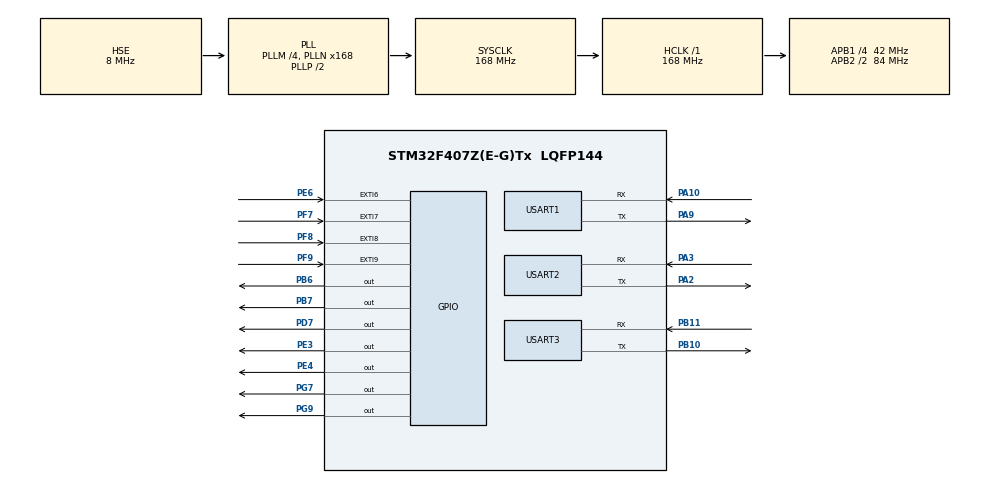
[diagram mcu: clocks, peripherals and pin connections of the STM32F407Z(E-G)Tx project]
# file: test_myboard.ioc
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Mcu.Family=STM32F4
Mcu.Name=STM32F407Z(E-G)Tx
Mcu.Package=LQFP144
NVIC.EXTI9_5_IRQn=true\:0\:0\:false\:false\:true\:true\:true
NVIC.FLASH_IRQn=true\:0\:0\:false\:false\:true\:true\:true
NVIC.FPU_IRQn=true\:0\:0\:false\:false\:true\:true\:false
NVIC.PVD_IRQn=true\:0\:0\:false\:false\:true\:true\:true
NVIC.PriorityGroup=NVIC_PRIORITYGROUP_2
NVIC.RCC_IRQn=true\:0\:0\:false\:false\:true\:true\:false
NVIC.TIM1_UP_TIM10_IRQn=true\:0\:0\:false\:false\:true\:false\:true
NVIC.TimeBase=TIM1_UP_TIM10_IRQn
NVIC.TimeBaseIP=TIM1
NVIC.USART1_IRQn=true\:0\:0\:false\:false\:true\:true\:true
NVIC.USART2_IRQn=true\:0\:0\:false\:false\:true\:true\:true
NVIC.USART3_IRQn=true\:0\:0\:false\:false\:true\:true\:true
PA10.Mode=Asynchronous
PA10.Signal=USART1_RX
PA2.Mode=Asynchronous
PA2.Signal=USART2_TX
PA3.Mode=Asynchronous
PA3.Signal=USART2_RX
PA9.Mode=Asynchronous
PA9.Signal=USART1_TX
PB10.Mode=Asynchronous
PB10.Signal=USART3_TX
PB11.Mode=Asynchronous
PB11.Signal=USART3_RX
PB6.Signal=GPIO_Output
PB7.Signal=GPIO_Output
PC14-OSC32_IN.Mode=LSE-External-Oscillator
PC14-OSC32_IN.Signal=RCC_OSC32_IN
PC15-OSC32_OUT.Mode=LSE-External-Oscillator
PC15-OSC32_OUT.Signal=RCC_OSC32_OUT
PD7.PinState=GPIO_PIN_RESET
PD7.Signal=GPIO_Output
PE3.PinState=GPIO_PIN_SET
PE3.Signal=GPIO_Output
PE4.PinState=GPIO_PIN_SET
PE4.Signal=GPIO_Output
PE6.GPIO_ModeDefaultEXTI=GPIO_MODE_IT_FALLING
PE6.Signal=GPXTI6
PF7.GPIO_ModeDefaultEXTI=GPIO_MODE_IT_FALLING
PF7.Signal=GPXTI7
PF8.GPIO_ModeDefaultEXTI=GPIO_MODE_IT_FALLING
PF8.Signal=GPXTI8
PF9.GPIO_ModeDefaultEXTI=GPIO_MODE_IT_FALLING
PF9.Signal=GPXTI9
PG7.Signal=GPIO_Output
PG9.PinState=GPIO_PIN_SET
PG9.Signal=GPIO_Output
PH0-OSC_IN.Mode=HSE-External-Oscillator
PH0-OSC_IN.Signal=RCC_OSC_IN
PH1-OSC_OUT.Mode=HSE-External-Oscillator
PH1-OSC_OUT.Signal=RCC_OSC_OUT
ProjectManager.HeapSize=0x200
ProjectManager.StackSize=0x400
ProjectManager.TargetToolchain=MDK-ARM V5.27
RCC.48MHZClocksFreq_Value=84000000
RCC.AHBFreq_Value=168000000
RCC.APB1CLKDivider=RCC_HCLK_DIV4
RCC.APB1Freq_Value=42000000
RCC.APB1TimFreq_Value=84000000
RCC.APB2CLKDivider=RCC_HCLK_DIV2
RCC.APB2Freq_Value=84000000
RCC.APB2TimFreq_Value=168000000
RCC.CortexFreq_Value=168000000
RCC.HCLKFreq_Value=168000000
RCC.HSE_VALUE=8000000
RCC.HSI_VALUE=16000000
RCC.PLLM=4
RCC.PLLN=168
RCC.PLLSourceVirtual=RCC_PLLSOURCE_HSE
RCC.SYSCLKFreq_VALUE=168000000
RCC.SYSCLKSource=RCC_SYSCLKSOURCE_PLLCLK
RCC.VCOOutputFreq_Value=336000000
USART1.VirtualMode=VM_ASYNC
USART2.VirtualMode=VM_ASYNC
USART3.VirtualMode=VM_ASYNC
VP_SYS_VS_tim1.Mode=TIM1
board=custom

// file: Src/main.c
/* USER CODE BEGIN Header */
/**
  ******************************************************************************
  * @file           : main.c
  * @brief          : Main program body
  ******************************************************************************
  * @attention
  *
  * <h2><center>&copy; Copyright (c) 2020 STMicroelectronics.
  * All rights reserved.</center></h2>
  *
  * This software component is licensed by ST under BSD 3-Clause license,
  * the "License"; You may not use this file except in compliance with the
  * License. You may obtain a copy of the License at:
  *                        opensource.org/licenses/BSD-3-Clause
  *
  ******************************************************************************
  */
/* USER CODE END Header */

#include "main.h"

/* USER CODE BEGIN Includes */
#include <stdio.h>
/* USER CODE END Includes */

UART_HandleTypeDef huart1;
UART_HandleTypeDef huart2;
UART_HandleTypeDef huart3;

void SystemClock_Config(void);
static void MX_GPIO_Init(void);
static void MX_USART1_UART_Init(void);
static void MX_USART2_UART_Init(void);
static void MX_USART3_UART_Init(void);
/* USER CODE BEGIN PFP */
int fputc(int ch,FILE *f)
{
  HAL_UART_Transmit(&huart1,(uint8_t *)&ch,1,0xFFFF);
	return ch;
}
/* USER CODE END PFP */

int main(void)
{
  /* USER CODE BEGIN 1 */
 int i = 0;
  /* USER CODE END 1 */

  /* MCU Configuration--------------------------------------------------------*/

  /* Reset of all peripherals, Initializes the Flash interface and the Systick. */
  HAL_Init();

  /* Configure the system clock */
  SystemClock_Config();

  /* Initialize all configured peripherals */
  MX_GPIO_Init();
  MX_USART1_UART_Init();
  MX_USART2_UART_Init();
  MX_USART3_UART_Init();

  /* Infinite loop */
  /* USER CODE BEGIN WHILE */
  while (1)
  {
		printf("test myboard %d\r\n",i++);

		HAL_Delay(1000);
    /* USER CODE END WHILE */

  }
}

void SystemClock_Config(void)
{
  RCC_OscInitTypeDef RCC_OscInitStruct = {0};
  RCC_ClkInitTypeDef RCC_ClkInitStruct = {0};

  /** Configure the main internal regulator output voltage
  */
  __HAL_RCC_PWR_CLK_ENABLE();
  __HAL_PWR_VOLTAGESCALING_CONFIG(PWR_REGULATOR_VOLTAGE_SCALE1);
  /** Initializes the CPU, AHB and APB busses clocks
  */
  RCC_OscInitStruct.OscillatorType = RCC_OSCILLATORTYPE_HSE;
  RCC_OscInitStruct.HSEState = RCC_HSE_ON;
  RCC_OscInitStruct.PLL.PLLState = RCC_PLL_ON;
  RCC_OscInitStruct.PLL.PLLSource = RCC_PLLSOURCE_HSE;
  RCC_OscInitStruct.PLL.PLLM = 4;
  RCC_OscInitStruct.PLL.PLLN = 168;
  RCC_OscInitStruct.PLL.PLLP = RCC_PLLP_DIV2;
  RCC_OscInitStruct.PLL.PLLQ = 4;
  if (HAL_RCC_OscConfig(&RCC_OscInitStruct) != HAL_OK)
  {
    Error_Handler();
  }
  /** Initializes the CPU, AHB and APB busses clocks
  */
  RCC_ClkInitStruct.ClockType = RCC_CLOCKTYPE_HCLK|RCC_CLOCKTYPE_SYSCLK
                              |RCC_CLOCKTYPE_PCLK1|RCC_CLOCKTYPE_PCLK2;
  RCC_ClkInitStruct.SYSCLKSource = RCC_SYSCLKSOURCE_PLLCLK;
  RCC_ClkInitStruct.AHBCLKDivider = RCC_SYSCLK_DIV1;
  RCC_ClkInitStruct.APB1CLKDivider = RCC_HCLK_DIV4;
  RCC_ClkInitStruct.APB2CLKDivider = RCC_HCLK_DIV2;

  if (HAL_RCC_ClockConfig(&RCC_ClkInitStruct, FLASH_LATENCY_5) != HAL_OK)
  {
    Error_Handler();
  }
}

static void MX_USART1_UART_Init(void)
{

  huart1.Instance = USART1;
  huart1.Init.BaudRate = 115200;
  huart1.Init.WordLength = UART_WORDLENGTH_8B;
  huart1.Init.StopBits = UART_STOPBITS_1;
  huart1.Init.Parity = UART_PARITY_NONE;
  huart1.Init.Mode = UART_MODE_TX_RX;
  huart1.Init.HwFlowCtl = UART_HWCONTROL_NONE;
  huart1.Init.OverSampling = UART_OVERSAMPLING_16;
  if (HAL_UART_Init(&huart1) != HAL_OK)
  {
    Error_Handler();
  }

}

static void MX_USART2_UART_Init(void)
{

  huart2.Instance = USART2;
  huart2.Init.BaudRate = 115200;
  huart2.Init.WordLength = UART_WORDLENGTH_8B;
  huart2.Init.StopBits = UART_STOPBITS_1;
  huart2.Init.Parity = UART_PARITY_NONE;
  huart2.Init.Mode = UART_MODE_TX_RX;
  huart2.Init.HwFlowCtl = UART_HWCONTROL_NONE;
  huart2.Init.OverSampling = UART_OVERSAMPLING_16;
  if (HAL_UART_Init(&huart2) != HAL_OK)
  {
    Error_Handler();
  }

}

static void MX_USART3_UART_Init(void)
{

  huart3.Instance = USART3;
  huart3.Init.BaudRate = 115200;
  huart3.Init.WordLength = UART_WORDLENGTH_8B;
  huart3.Init.StopBits = UART_STOPBITS_1;
  huart3.Init.Parity = UART_PARITY_NONE;
  huart3.Init.Mode = UART_MODE_TX_RX;
  huart3.Init.HwFlowCtl = UART_HWCONTROL_NONE;
  huart3.Init.OverSampling = UART_OVERSAMPLING_16;
  if (HAL_UART_Init(&huart3) != HAL_OK)
  {
    Error_Handler();
  }

}

static void MX_GPIO_Init(void)
{
  GPIO_InitTypeDef GPIO_InitStruct = {0};

  /* GPIO Ports Clock Enable */
  __HAL_RCC_GPIOE_CLK_ENABLE();
  __HAL_RCC_GPIOC_CLK_ENABLE();
  __HAL_RCC_GPIOF_CLK_ENABLE();
  __HAL_RCC_GPIOH_CLK_ENABLE();
  __HAL_RCC_GPIOA_CLK_ENABLE();
  __HAL_RCC_GPIOB_CLK_ENABLE();
  __HAL_RCC_GPIOG_CLK_ENABLE();
  __HAL_RCC_GPIOD_CLK_ENABLE();

  /*Configure GPIO pin Output Level */
  HAL_GPIO_WritePin(GPIOE, GPIO_PIN_3|GPIO_PIN_4, GPIO_PIN_SET);

  /*Configure GPIO pin Output Level */
  HAL_GPIO_WritePin(GPIOG, GPIO_PIN_7, GPIO_PIN_RESET);

  /*Configure GPIO pin Output Level */
  HAL_GPIO_WritePin(GPIOD, GPIO_PIN_7, GPIO_PIN_RESET);

  /*Configure GPIO pin Output Level */
  HAL_GPIO_WritePin(GPIOG, GPIO_PIN_9, GPIO_PIN_SET);

  /*Configure GPIO pin Output Level */
  HAL_GPIO_WritePin(GPIOB, GPIO_PIN_6|GPIO_PIN_7, GPIO_PIN_RESET);

  /*Configure GPIO pins : PE3 PE4 */
  GPIO_InitStruct.Pin = GPIO_PIN_3|GPIO_PIN_4;
  GPIO_InitStruct.Mode = GPIO_MODE_OUTPUT_PP;
  GPIO_InitStruct.Pull = GPIO_NOPULL;
  GPIO_InitStruct.Speed = GPIO_SPEED_FREQ_LOW;
  HAL_GPIO_Init(GPIOE, &GPIO_InitStruct);

  /*Configure GPIO pin : PE6 */
  GPIO_InitStruct.Pin = GPIO_PIN_6;
  GPIO_InitStruct.Mode = GPIO_MODE_IT_FALLING;
  GPIO_InitStruct.Pull = GPIO_NOPULL;
  HAL_GPIO_Init(GPIOE, &GPIO_InitStruct);

  /*Configure GPIO pins : PF7 PF8 PF9 */
  GPIO_InitStruct.Pin = GPIO_PIN_7|GPIO_PIN_8|GPIO_PIN_9;
  GPIO_InitStruct.Mode = GPIO_MODE_IT_FALLING;
  GPIO_InitStruct.Pull = GPIO_NOPULL;
  HAL_GPIO_Init(GPIOF, &GPIO_InitStruct);

  /*Configure GPIO pins : PG7 PG9 */
  GPIO_InitStruct.Pin = GPIO_PIN_7|GPIO_PIN_9;
  GPIO_InitStruct.Mode = GPIO_MODE_OUTPUT_PP;
  GPIO_InitStruct.Pull = GPIO_NOPULL;
  GPIO_InitStruct.Speed = GPIO_SPEED_FREQ_LOW;
  HAL_GPIO_Init(GPIOG, &GPIO_InitStruct);

  /*Configure GPIO pin : PD7 */
  GPIO_InitStruct.Pin = GPIO_PIN_7;
  GPIO_InitStruct.Mode = GPIO_MODE_OUTPUT_PP;
  GPIO_InitStruct.Pull = GPIO_NOPULL;
  GPIO_InitStruct.Speed = GPIO_SPEED_FREQ_LOW;
  HAL_GPIO_Init(GPIOD, &GPIO_InitStruct);

  /*Configure GPIO pins : PB6 PB7 */
  GPIO_InitStruct.Pin = GPIO_PIN_6|GPIO_PIN_7;
  GPIO_InitStruct.Mode = GPIO_MODE_OUTPUT_PP;
  GPIO_InitStruct.Pull = GPIO_NOPULL;
  GPIO_InitStruct.Speed = GPIO_SPEED_FREQ_LOW;
  HAL_GPIO_Init(GPIOB, &GPIO_InitStruct);

  /* EXTI interrupt init*/
  HAL_NVIC_SetPriority(EXTI9_5_IRQn, 0, 0);
  HAL_NVIC_EnableIRQ(EXTI9_5_IRQn);

}

 /**
  * @brief  Period elapsed callback in non blocking mode
  * @note   This function is called  when TIM1 interrupt took place, inside
  * HAL_TIM_IRQHandler(). It makes a direct call to HAL_IncTick() to increment
  * a global variable "uwTick" used as application time base.
  * @param  htim : TIM handle
  * @retval None
  */
void HAL_TIM_PeriodElapsedCallback(TIM_HandleTypeDef *htim)
{
  if (htim->Instance == TIM1) {
    HAL_IncTick();
  }
}

void Error_Handler(void)
{
}

/************************ (C) COPYRIGHT STMicroelectronics *****END OF FILE****/
